AUTOSAR XML (schema 00049)
standard types defined: uint8, uint16
package /ControlSWC_Config/Types/ImplementationDataTypes
  impl type TYP_ExchangedData8: category=VALUE, base-type=uint8
  impl type TYP_ExchangedData16: category=VALUE, base-type=uint16
package /ControlSWC_Config/Types/SwAddrMethods
  sw addr method CODE: section-type=CODE
  sw addr method CONST: section-type=CONST
  sw addr method VAR: section-type=VAR
package /ControlSWC_Config/Types/Units
  unit NoUnit: factor-si-to-unit=1, offset-si-to-unit=0
package /ControlSWC_Config/Interfaces
  sender receiver interface IF_ExchangedData
    data DE_ExchangedData: category=VALUE, sw-calibration-access=READ-ONLY, type=TYP_ExchangedData
    data DE_ExchangedEvent: category=VALUE, sw-calibration-access=READ-ONLY, sw-impl-policy=QUEUED, type=TYP_ExchangedData
package /ControlSWC_Config/SWCs
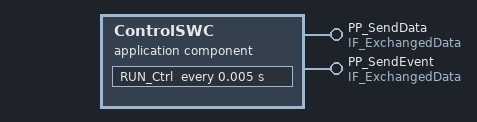
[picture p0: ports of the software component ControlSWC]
  application sw component type ControlSWC
    provide port PP_SendData: nonqueued-sender-com-spec{data-element=DE_ExchangedData, init-value=0}, provided-interface=IF_ExchangedData
    provide port PP_SendEvent: queued-sender-com-spec=data-element=DE_ExchangedEvent, provided-interface=IF_ExchangedData
    behavior ControlSWC_IB: handle-termination-and-restart=NO-SUPPORT
      timing event Ev_Ti_RUN_Ctrl: start-on-event=RUN_Ctrl, period=0.005
      runnable RUN_Ctrl
        data-send-points:
          access VDP_ExplWrite: accessed-variable=PP_SendData.DE_ExchangedData
          access VDP_Send: accessed-variable=PP_SendEvent.DE_ExchangedEvent
        data-write-access:
          access VDP_ImplWrite: accessed-variable=PP_SendData.DE_ExchangedData
